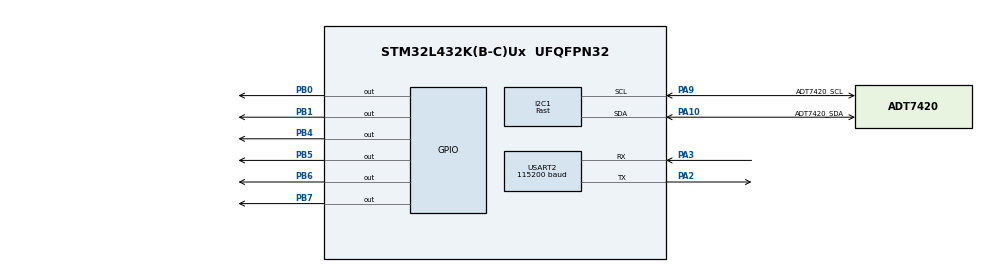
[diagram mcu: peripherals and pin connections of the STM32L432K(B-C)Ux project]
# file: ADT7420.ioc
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I2C1.I2C_Speed_Mode=I2C_Fast
I2C1.Speed=400
I2C1.Timing=0x0010061A
Mcu.Family=STM32L4
Mcu.Name=STM32L432K(B-C)Ux
Mcu.Package=UFQFPN32
NVIC.PriorityGroup=NVIC_PRIORITYGROUP_4
NVIC.TIM2_IRQn=true\:0\:0\:false\:false\:true\:true\:true
NVIC.USART2_IRQn=true\:0\:0\:false\:false\:true\:true\:true
PA10.GPIO_Label=ADT7420_SDA
PA10.GPIO_PuPdOD=GPIO_PULLUP
PA10.Mode=I2C
PA10.Signal=I2C1_SDA
PA2.Mode=Asynchronous
PA2.Signal=USART2_TX
PA3.Mode=Asynchronous
PA3.Signal=USART2_RX
PA9.GPIO_Label=ADT7420_SCL
PA9.GPIO_PuPdOD=GPIO_PULLUP
PA9.Mode=I2C
PA9.Signal=I2C1_SCL
PB0.GPIO_PuPd=GPIO_PULLDOWN
PB0.Signal=GPIO_Output
PB1.GPIO_PuPd=GPIO_PULLDOWN
PB1.Signal=GPIO_Output
PB4\ (NJTRST).GPIO_PuPd=GPIO_PULLDOWN
PB4\ (NJTRST).Signal=GPIO_Output
PB5.GPIO_PuPd=GPIO_PULLDOWN
PB5.Signal=GPIO_Output
PB6.GPIO_PuPd=GPIO_PULLDOWN
PB6.Signal=GPIO_Output
PB7.GPIO_PuPd=GPIO_PULLDOWN
PB7.Signal=GPIO_Output
ProjectManager.HeapSize=0x200
ProjectManager.StackSize=0x400
ProjectManager.TargetToolchain=STM32CubeIDE
RCC.ADCFreq_Value=64000000
RCC.AHBFreq_Value=16000000
RCC.APB1Freq_Value=16000000
RCC.APB1TimFreq_Value=16000000
RCC.APB2Freq_Value=16000000
RCC.APB2TimFreq_Value=16000000
RCC.CortexFreq_Value=16000000
RCC.HCLKFreq_Value=16000000
RCC.HSE_VALUE=8000000
RCC.HSI48_VALUE=48000000
RCC.HSI_VALUE=16000000
RCC.LSE_VALUE=32768
RCC.MSIClockRange=RCC_MSIRANGE_8
RCC.MSI_VALUE=16000000
RCC.SYSCLKFreq_VALUE=16000000
RCC.USBFreq_Value=64000000
RCC.VCOOutputFreq_Value=128000000
TIM2.Period=999
TIM2.Prescaler=15999
USART2.BaudRate=115200
USART2.VirtualMode-Asynchronous=VM_ASYNC
VP_TIM2_VS_ClockSourceINT.Mode=Internal
board=custom

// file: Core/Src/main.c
/* USER CODE BEGIN Header */
/**
  ******************************************************************************
  * @file           : main.c
  * @brief          : Main program body
  ******************************************************************************
  * @attention
  *
  * <h2><center>&copy; Copyright (c) 2020 STMicroelectronics.
  * All rights reserved.</center></h2>
  *
  * This software component is licensed by ST under BSD 3-Clause license,
  * the "License"; You may not use this file except in compliance with the
  * License. You may obtain a copy of the License at:
  *                        opensource.org/licenses/BSD-3-Clause
  *
  ******************************************************************************
  */
/* USER CODE END Header */
#include "main.h"

/* USER CODE BEGIN Includes */
#include "demo.h"
/* USER CODE END Includes */

void SystemClock_Config(void);
static void MX_GPIO_Init(void);
static void MX_I2C1_Init(void);
static void MX_USART2_UART_Init(void);
static void MX_TIM2_Init(void);

int main(void)
{

  /* MCU Configuration--------------------------------------------------------*/

  /* Reset of all peripherals, Initializes the Flash interface and the Systick. */

  LL_APB2_GRP1_EnableClock(LL_APB2_GRP1_PERIPH_SYSCFG);
  LL_APB1_GRP1_EnableClock(LL_APB1_GRP1_PERIPH_PWR);

  NVIC_SetPriorityGrouping(NVIC_PRIORITYGROUP_4);

  /* System interrupt init*/

  /* Configure the system clock */
  SystemClock_Config();

  /* Initialize all configured peripherals */
  MX_GPIO_Init();
  MX_I2C1_Init();
  MX_USART2_UART_Init();
  MX_TIM2_Init();
  /* USER CODE BEGIN 2 */
  sys_init();
  /* USER CODE END 2 */

  /* Infinite loop */
  /* USER CODE BEGIN WHILE */
  while (1) {
    // Only read the sensor if timer 2 overflowed, else go straight back to sleep
    if (timer2_overflow_flag) {
      timer2_overflow_flag = false;
      read_adt7420();
    }
    SLEEP_MODE();
    /* USER CODE END WHILE */

  }
}

void SystemClock_Config(void)
{
  LL_FLASH_SetLatency(LL_FLASH_LATENCY_0);
  while(LL_FLASH_GetLatency()!= LL_FLASH_LATENCY_0)
  {
  }
  LL_PWR_SetRegulVoltageScaling(LL_PWR_REGU_VOLTAGE_SCALE1);
  LL_RCC_MSI_Enable();

   /* Wait till MSI is ready */
  while(LL_RCC_MSI_IsReady() != 1)
  {

  }
  LL_RCC_MSI_EnableRangeSelection();
  LL_RCC_MSI_SetRange(LL_RCC_MSIRANGE_8);
  LL_RCC_MSI_SetCalibTrimming(0);
  LL_RCC_SetSysClkSource(LL_RCC_SYS_CLKSOURCE_MSI);

   /* Wait till System clock is ready */
  while(LL_RCC_GetSysClkSource() != LL_RCC_SYS_CLKSOURCE_STATUS_MSI)
  {

  }
  LL_RCC_SetAHBPrescaler(LL_RCC_SYSCLK_DIV_1);
  LL_RCC_SetAPB1Prescaler(LL_RCC_APB1_DIV_1);
  LL_RCC_SetAPB2Prescaler(LL_RCC_APB2_DIV_1);

  LL_Init1msTick(16000000);

  LL_SetSystemCoreClock(16000000);
  LL_RCC_SetUSARTClockSource(LL_RCC_USART2_CLKSOURCE_PCLK1);
  LL_RCC_SetI2CClockSource(LL_RCC_I2C1_CLKSOURCE_PCLK1);
}

static void MX_I2C1_Init(void)
{

  LL_I2C_InitTypeDef I2C_InitStruct = {0};

  LL_GPIO_InitTypeDef GPIO_InitStruct = {0};

  LL_AHB2_GRP1_EnableClock(LL_AHB2_GRP1_PERIPH_GPIOA);
  /**I2C1 GPIO Configuration
  PA9   ------> I2C1_SCL
  PA10   ------> I2C1_SDA
  */
  GPIO_InitStruct.Pin = ADT7420_SCL_Pin|ADT7420_SDA_Pin;
  GPIO_InitStruct.Mode = LL_GPIO_MODE_ALTERNATE;
  GPIO_InitStruct.Speed = LL_GPIO_SPEED_FREQ_VERY_HIGH;
  GPIO_InitStruct.OutputType = LL_GPIO_OUTPUT_OPENDRAIN;
  GPIO_InitStruct.Pull = LL_GPIO_PULL_UP;
  GPIO_InitStruct.Alternate = LL_GPIO_AF_4;
  LL_GPIO_Init(GPIOA, &GPIO_InitStruct);

  /* Peripheral clock enable */
  LL_APB1_GRP1_EnableClock(LL_APB1_GRP1_PERIPH_I2C1);

  /** I2C Initialization
  */
  LL_I2C_EnableAutoEndMode(I2C1);
  LL_I2C_DisableOwnAddress2(I2C1);
  LL_I2C_DisableGeneralCall(I2C1);
  LL_I2C_EnableClockStretching(I2C1);
  I2C_InitStruct.PeripheralMode = LL_I2C_MODE_I2C;
  I2C_InitStruct.Timing = 0x0010061A;
  I2C_InitStruct.AnalogFilter = LL_I2C_ANALOGFILTER_ENABLE;
  I2C_InitStruct.DigitalFilter = 0;
  I2C_InitStruct.OwnAddress1 = 0;
  I2C_InitStruct.TypeAcknowledge = LL_I2C_ACK;
  I2C_InitStruct.OwnAddrSize = LL_I2C_OWNADDRESS1_7BIT;
  LL_I2C_Init(I2C1, &I2C_InitStruct);
  LL_I2C_SetOwnAddress2(I2C1, 0, LL_I2C_OWNADDRESS2_NOMASK);

}

static void MX_TIM2_Init(void)
{

  LL_TIM_InitTypeDef TIM_InitStruct = {0};

  /* Peripheral clock enable */
  LL_APB1_GRP1_EnableClock(LL_APB1_GRP1_PERIPH_TIM2);

  /* TIM2 interrupt Init */
  NVIC_SetPriority(TIM2_IRQn, NVIC_EncodePriority(NVIC_GetPriorityGrouping(),0, 0));
  NVIC_EnableIRQ(TIM2_IRQn);

  TIM_InitStruct.Prescaler = 15999;
  TIM_InitStruct.CounterMode = LL_TIM_COUNTERMODE_UP;
  TIM_InitStruct.Autoreload = 999;
  TIM_InitStruct.ClockDivision = LL_TIM_CLOCKDIVISION_DIV1;
  LL_TIM_Init(TIM2, &TIM_InitStruct);
  LL_TIM_DisableARRPreload(TIM2);
  LL_TIM_SetClockSource(TIM2, LL_TIM_CLOCKSOURCE_INTERNAL);
  LL_TIM_SetTriggerOutput(TIM2, LL_TIM_TRGO_RESET);
  LL_TIM_DisableMasterSlaveMode(TIM2);
  /* USER CODE BEGIN TIM2_Init 2 */
  // Enable counter & overflow event interrupt
  LL_TIM_EnableCounter(TIM2);
  LL_TIM_SetUpdateSource(TIM2, LL_TIM_UPDATESOURCE_COUNTER);
  LL_TIM_EnableUpdateEvent(TIM2);
  LL_TIM_EnableIT_UPDATE(TIM2);
  /* USER CODE END TIM2_Init 2 */

}

static void MX_USART2_UART_Init(void)
{

  LL_USART_InitTypeDef USART_InitStruct = {0};

  LL_GPIO_InitTypeDef GPIO_InitStruct = {0};

  /* Peripheral clock enable */
  LL_APB1_GRP1_EnableClock(LL_APB1_GRP1_PERIPH_USART2);

  LL_AHB2_GRP1_EnableClock(LL_AHB2_GRP1_PERIPH_GPIOA);
  /**USART2 GPIO Configuration
  PA2   ------> USART2_TX
  PA3   ------> USART2_RX
  */
  GPIO_InitStruct.Pin = LL_GPIO_PIN_2|LL_GPIO_PIN_3;
  GPIO_InitStruct.Mode = LL_GPIO_MODE_ALTERNATE;
  GPIO_InitStruct.Speed = LL_GPIO_SPEED_FREQ_VERY_HIGH;
  GPIO_InitStruct.OutputType = LL_GPIO_OUTPUT_PUSHPULL;
  GPIO_InitStruct.Pull = LL_GPIO_PULL_NO;
  GPIO_InitStruct.Alternate = LL_GPIO_AF_7;
  LL_GPIO_Init(GPIOA, &GPIO_InitStruct);

  /* USART2 interrupt Init */
  NVIC_SetPriority(USART2_IRQn, NVIC_EncodePriority(NVIC_GetPriorityGrouping(),0, 0));
  NVIC_EnableIRQ(USART2_IRQn);

  USART_InitStruct.BaudRate = 115200;
  USART_InitStruct.DataWidth = LL_USART_DATAWIDTH_8B;
  USART_InitStruct.StopBits = LL_USART_STOPBITS_1;
  USART_InitStruct.Parity = LL_USART_PARITY_NONE;
  USART_InitStruct.TransferDirection = LL_USART_DIRECTION_TX_RX;
  USART_InitStruct.HardwareFlowControl = LL_USART_HWCONTROL_NONE;
  USART_InitStruct.OverSampling = LL_USART_OVERSAMPLING_16;
  LL_USART_Init(USART2, &USART_InitStruct);
  LL_USART_ConfigAsyncMode(USART2);
  LL_USART_Enable(USART2);

}

static void MX_GPIO_Init(void)
{
  LL_GPIO_InitTypeDef GPIO_InitStruct = {0};

  /* GPIO Ports Clock Enable */
  LL_AHB2_GRP1_EnableClock(LL_AHB2_GRP1_PERIPH_GPIOA);
  LL_AHB2_GRP1_EnableClock(LL_AHB2_GRP1_PERIPH_GPIOB);

  /**/
  LL_GPIO_ResetOutputPin(GPIOB, LL_GPIO_PIN_0|LL_GPIO_PIN_1|LL_GPIO_PIN_4|LL_GPIO_PIN_5
                          |LL_GPIO_PIN_6|LL_GPIO_PIN_7);

  /**/
  GPIO_InitStruct.Pin = LL_GPIO_PIN_0|LL_GPIO_PIN_1|LL_GPIO_PIN_4|LL_GPIO_PIN_5
                          |LL_GPIO_PIN_6|LL_GPIO_PIN_7;
  GPIO_InitStruct.Mode = LL_GPIO_MODE_OUTPUT;
  GPIO_InitStruct.Speed = LL_GPIO_SPEED_FREQ_LOW;
  GPIO_InitStruct.OutputType = LL_GPIO_OUTPUT_PUSHPULL;
  GPIO_InitStruct.Pull = LL_GPIO_PULL_DOWN;
  LL_GPIO_Init(GPIOB, &GPIO_InitStruct);

}

void Error_Handler(void)
{
}

/************************ (C) COPYRIGHT STMicroelectronics *****END OF FILE****/
